# ATSAML11E15A device description
Architecture: CORTEX-M23; Family: SAML; Series: SAML11
Registers are 32-bit, read-write, reset 0x0 unless marked. A register's access mark holds for its fields unless they carry their own. Offsets are from the block's base; [hi:lo] are bit positions; {n}, {i} and the like mark numbered series; 'fields as' and 'values as' point back to an identical list.

## BOCOR_FUSES — Non-Volatile Fuses
Instances: BOCOR_FUSES 0x0080C000 in fuses
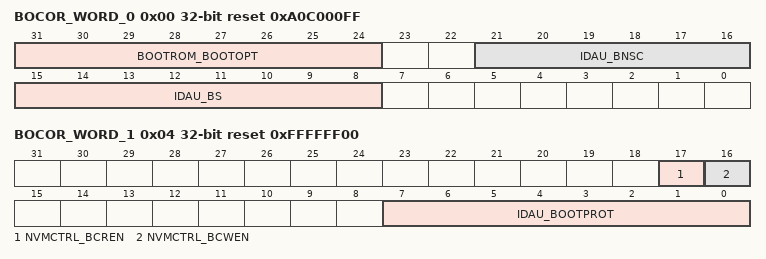
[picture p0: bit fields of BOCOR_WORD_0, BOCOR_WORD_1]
0x00 BOCOR_WORD_0 reset 0xA0C000FF — BOCOR Page Word 0
  [31:24] BOOTROM_BOOTOPT — Boot Option
  [21:16] IDAU_BNSC — Boot Non-Secure Callable
  [15:8] IDAU_BS — Boot Secure
0x04 BOCOR_WORD_1 reset 0xFFFFFF00 — BOCOR Page Word 1
  [17] NVMCTRL_BCREN — Boot Configuration Read Enable
  [16] NVMCTRL_BCWEN — Boot Configuration Write Enable
  [7:0] IDAU_BOOTPROT — Boot Protection
0x08 BOCOR_WORD_2 reset 0xDDE78140 — BOCOR Page Word 2
  [31:0] BOOTROM_BOCORCRC — CRC for BOCOR DWORD0
{0x0+4i} BOCOR_WORD_{i} reset 0xFFFFFFFF (i=4..7) — BOCOR Page Word {i}
  [31:0] BOOTROM_CEKEY0_{i-4} — Chip Erase Key 0 bits {32i-97}:{32i-128}
{0x0+4i} BOCOR_WORD_{i} reset 0xFFFFFFFF (i=8..11) — BOCOR Page Word {i}
  [31:0] BOOTROM_CEKEY1_{i-8} — Chip Erase Key 1 bits {32i-225}:{32i-256}
{0x0+4i} BOCOR_WORD_{i} reset 0xFFFFFFFF (i=12..15) — BOCOR Page Word {i}
  [31:0] BOOTROM_CEKEY2_{i-12} — Chip Erase Key 2 bits {32i-353}:{32i-384}
{0x0+4i} BOCOR_WORD_{i} reset 0xFFFFFFFF (i=16..19) — BOCOR Page Word {i}
  [31:0] BOOTROM_CRCKEY_{i-16} — CRC Key bits {32i-481}:{32i-512}
{0x0+4i} BOCOR_WORD_{i} reset 0xFFFFFFFF (i=20..27) — BOCOR Page Word {i}
  [31:0] BOOTROM_BOOTKEY_{i-20} — Secure Boot Key bits {32i-609}:{32i-640}
{0x0+4i} BOCOR_WORD_{i} reset 0xFFFFFFFF (i=56..63) — BOCOR Page Word {i}
  [31:0] BOOTROM_BOCORHASH_{i-56} — Boot Configuration Row Hash bits {32i-1761}:{32i-1792}

## SW_CALIB_FUSES — Non-Volatile Fuses
Instances: SW_CALIB_FUSES 0x00806020 in fuses
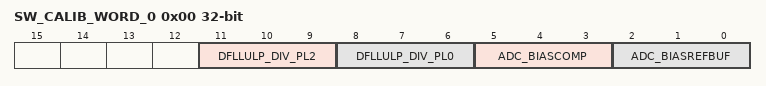
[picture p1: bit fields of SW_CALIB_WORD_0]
0x00 SW_CALIB_WORD_0 ro reset not defined — SW_CALIB Page Word 0
  [11:9] DFLLULP_DIV_PL2 — DFLLULP DIV at PL2
  [8:6] DFLLULP_DIV_PL0 — DFLLULP DIV at PL0
  [5:3] ADC_BIASCOMP — ADC Comparator Scaling
  [2:0] ADC_BIASREFBUF — ADC Bias Reference Buffer Scaling

## TEMP_LOG_FUSES — Non-Volatile Fuses
Instances: TEMP_LOG_FUSES 0x00806038 in fuses
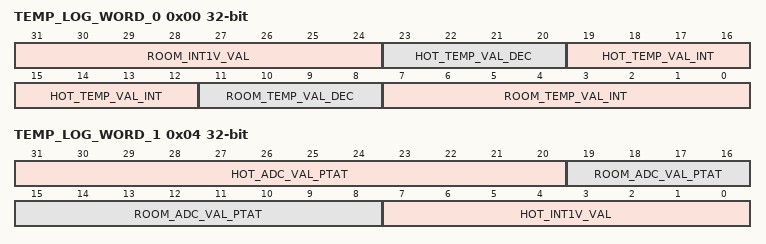
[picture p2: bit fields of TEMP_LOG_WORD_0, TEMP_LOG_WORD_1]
0x00 TEMP_LOG_WORD_0 ro reset not defined — TEMP_LOG Page Word 0
  [31:24] ROOM_INT1V_VAL — 2's complement of the internal 1V reference drift at room temperature (versus a 1.0 centered value)
  [23:20] HOT_TEMP_VAL_DEC — Decimal part of hot temperature
  [19:12] HOT_TEMP_VAL_INT — Integer part of hot temperature in oC
  [11:8] ROOM_TEMP_VAL_DEC — Decimal part of room temperature
  [7:0] ROOM_TEMP_VAL_INT — Integer part of room temperature in oC
0x04 TEMP_LOG_WORD_1 ro reset not defined — TEMP_LOG Page Word 1
  [31:20] HOT_ADC_VAL_PTAT — 12-bit ADC conversion at hot temperature PTAT
  [19:8] ROOM_ADC_VAL_PTAT — 12-bit ADC conversion at room temperature PTAT
  [7:0] HOT_INT1V_VAL — 2's complement of the internal 1V reference drift at hot temperature (versus a 1.0 centered value)

## USER_FUSES — Non-Volatile Fuses
Instances: USER_FUSES 0x00804000 in fuses
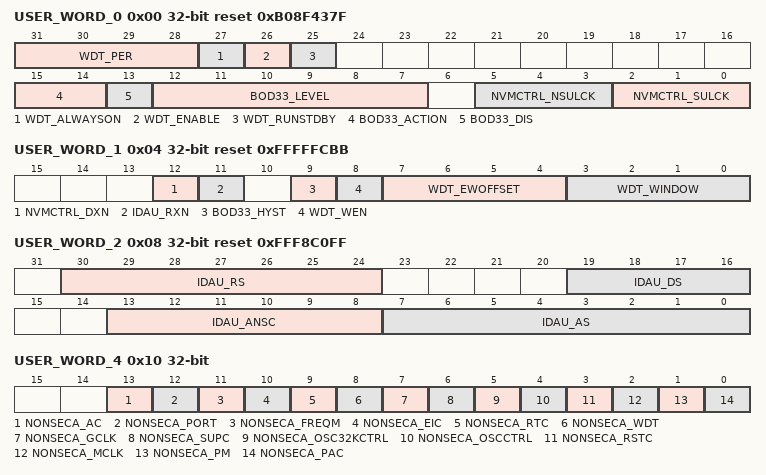
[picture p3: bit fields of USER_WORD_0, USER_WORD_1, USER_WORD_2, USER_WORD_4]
0x00 USER_WORD_0 reset 0xB08F437F — USER Page Word 0
  [31:28] WDT_PER — WDT Period
    0=CYC8 (8 clock cycles); 1=CYC16 (16 clock cycles); 2=CYC32 (32 clock cycles); 3=CYC64 (64 clock cycles); 4=CYC128 (128 clock cycles); 5=CYC256 (256 clock cycles); 6=CYC512 (512 clock cycles); 7=CYC1024 (1024 clock cycles); 8=CYC2048 (2048 clock cycles); 9=CYC4096 (4096 clock cycles); 10=CYC8192 (8192 clock cycles); 11=CYC16384 (16384 clock cycles)
  [27] WDT_ALWAYSON
  [26] WDT_ENABLE
  [25] WDT_RUNSTDBY — WDT Run During Standby
  [15:14] BOD33_ACTION
    0=NONE (No action); 1=RESET (The BOD33 generates a reset); 2=INT (The BOD33 generates an interrupt)
  [13] BOD33_DIS — BOD33 Disable
  [12:7] BOD33_LEVEL — BOD33 threshold Level
  [5:3] NVMCTRL_NSULCK — NVM Non-Secure Region Locks
  [2:0] NVMCTRL_SULCK — NVM Secure Region Locks
0x04 USER_WORD_1 reset 0xFFFFFCBB — USER Page Word 1
  [12] NVMCTRL_DXN — DATA FLASH is eXecute Never
  [11] IDAU_RXN — RAM is eXecute Never
  [9] BOD33_HYST — BOD33 Hysteresis
  [8] WDT_WEN — WDT Window Mode Enable
  [7:4] WDT_EWOFFSET — WDT Early Warning Offset
    values as USER_WORD_0.WDT_PER
  [3:0] WDT_WINDOW
    values as USER_WORD_0.WDT_PER
0x08 USER_WORD_2 reset 0xFFF8C0FF — USER Page Word 2
  [30:24] IDAU_RS — RAM Secure
  [19:16] IDAU_DS — Data Secure
  [13:8] IDAU_ANSC — Application Non-Secure Callable
  [7:0] IDAU_AS — Application Secure
0x0C USER_WORD_3 reset 0xFFFFFFFF — USER Page Word 3
  [0] NVMCTRL_URWEN — User Row Write Enable
0x10 USER_WORD_4 — USER Page Word 4
  [13] NONSECA_AC — AC Non-Secure
  [12] NONSECA_PORT — PORT Non-Secure
  [11] NONSECA_FREQM — FREQM Non-Secure
  [10] NONSECA_EIC — EIC Non-Secure
  [9] NONSECA_RTC — RTC Non-Secure
  [8] NONSECA_WDT — WDT Non-Secure
  [7] NONSECA_GCLK — GCLK Non-Secure
  [6] NONSECA_SUPC — SUPC Non-Secure
  [5] NONSECA_OSC32KCTRL — OSC32KCTRL Non-Secure
  [4] NONSECA_OSCCTRL — OSCCTRL Non-Secure
  [3] NONSECA_RSTC — RSTC Non-Secure
  [2] NONSECA_MCLK — MCLK Non-Secure
  [1] NONSECA_PM — PM Non-Secure
  [0] NONSECA_PAC — PAC Non-Secure
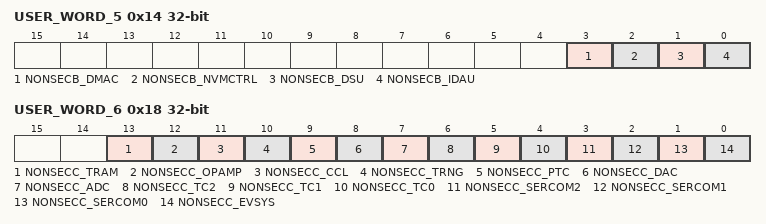
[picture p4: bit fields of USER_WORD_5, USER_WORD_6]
0x14 USER_WORD_5 — USER Page Word 5
  [3] NONSECB_DMAC — DMAC Non-Secure
  [2] NONSECB_NVMCTRL — NVMCTRL Non-Secure
  [1] NONSECB_DSU — DSU Non-Secure
  [0] NONSECB_IDAU — IDAU Non-Secure
0x18 USER_WORD_6 — USER Page Word 6
  [13] NONSECC_TRAM — TRAM Non-Secure
  [12] NONSECC_OPAMP — OPAMP Non-Secure
  [11] NONSECC_CCL — CCL Non-Secure
  [10] NONSECC_TRNG — TRNG Non-Secure
  [9] NONSECC_PTC — PTC Non-Secure
  [8] NONSECC_DAC — DAC Non-Secure
  [7] NONSECC_ADC — ADC Non-Secure
  [6] NONSECC_TC2 — TC2 Non-Secure
  [5] NONSECC_TC1 — TC1 Non-Secure
  [4] NONSECC_TC0 — TC0 Non-Secure
  [3] NONSECC_SERCOM2 — SERCOM2 Non-Secure
  [2] NONSECC_SERCOM1 — SERCOM1 Non-Secure
  [1] NONSECC_SERCOM0 — SERCOM0 Non-Secure
  [0] NONSECC_EVSYS — EVSYS Non-Secure
0x1C USER_WORD_7 reset 0x8433651E — USER Page Word 7
  [31:0] BOOTROM_USERCRC — CRC for USER[1,2,3] DWORDS

## Notices in the file
Copyright (c) 2019 Microchip Technology Inc.
SPDX-License-Identifier: Apache-2.0
Licensed under the Apache License, Version 2.0 (the "License");
you may not use this file except in compliance with the License.
You may obtain a copy of the License at
http://www.apache.org/licenses/LICENSE-2.0
Unless required by applicable law or agreed to in writing, software
distributed under the License is distributed on an "AS IS" BASIS,
WITHOUT WARRANTIES OR CONDITIONS OF ANY KIND, either express or implied.
See the License for the specific language governing permissions and
limitations under the License.
